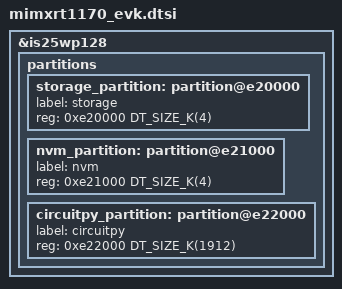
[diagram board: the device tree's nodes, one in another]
&is25wp128 {
	partitions {

		storage_partition: partition@e20000 {
			label = "storage";
			reg = <0xe20000 DT_SIZE_K(4)>;
		};

		nvm_partition: partition@e21000 {
			label = "nvm";
			reg = <0xe21000 DT_SIZE_K(4)>;
		};

		circuitpy_partition: partition@e22000 {
			label = "circuitpy";
			reg = <0xe22000 DT_SIZE_K(1912)>;
		};
	};
};
